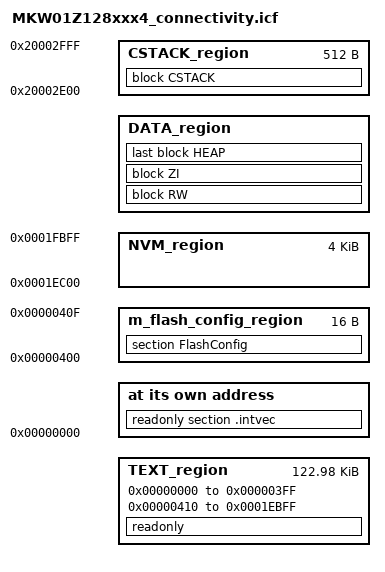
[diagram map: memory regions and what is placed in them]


/* By default, the NVM is not used. */
if (!isdefinedsymbol(gUseNVMLink_d)) {
  define symbol gUseNVMLink_d = 0;
}

/*** ROM: size 128k ***/
/*** RAM: size 16k ***/

/*-Memory Regions-*/
define symbol __region_ROM_start__   = 0x00000000;
define symbol __region_ROM_end__     = 0x0001FFFF;
define symbol __region_RAM_start__   = 0x1FFFF000;
define symbol __region_RAM_end__     = 0x20002FFF;

define symbol __vector_table_size__    =   48*4;
define symbol __ram_vector_table_size__ =  isdefinedsymbol(__ram_vector_table__) ? __vector_table_size__ : 0;



define symbol m_interrupts_start       = __region_ROM_start__;
define symbol m_interrupts_end         = m_interrupts_start + __vector_table_size__ - 1;
  
define symbol m_flash_config_start      = __region_ROM_start__ + 0x00000400;
define symbol m_flash_config_end        = m_flash_config_start + 0x0f;



/*-Sizes-*/
define symbol m_sector_size             = 1024; /* 1k flash sector size */

if (isdefinedsymbol(__stack_size__)) {
  define symbol __size_cstack__        = __stack_size__;
} else {
  define symbol __size_cstack__        = 512;
}

if (isdefinedsymbol(__heap_size__)) {
  define symbol __size_heap__          = __heap_size__;
} else {
  define symbol __size_heap__          = 0;
}


/*** FSL Product Info region ***/
define symbol m_fsl_prodInfo_start     = __region_ROM_end__ - m_sector_size + 1;
define symbol m_fsl_prodInfo_end       = __region_ROM_end__;
define exported symbol FREESCALE_PROD_DATA_BASE_ADDR = m_fsl_prodInfo_start;


/*** NVM Configuration ***/
if( gUseNVMLink_d )
{
  define exported symbol NV_STORAGE_SECTOR_SIZE = m_sector_size; /* 1k flash sector size */
  define exported symbol NV_STORAGE_MAX_SECTORS = 4;     	 /* NV_STORAGE_MAX_SECTORS * NV_STORAGE_SECTOR_SIZE = total NV Storage space */

  define exported symbol NV_STORAGE_START_ADDRESS = m_fsl_prodInfo_start - 1;
  define exported symbol NV_STORAGE_END_ADDRESS = NV_STORAGE_START_ADDRESS - (NV_STORAGE_MAX_SECTORS * NV_STORAGE_SECTOR_SIZE) + 1;
}

/*-Specials-*/
define symbol m_text_start             = m_interrupts_start;
if( gUseNVMLink_d )
{
  define symbol m_text_end               = NV_STORAGE_END_ADDRESS - 1;
}
else
{
  define symbol m_text_end               = m_fsl_prodInfo_start - 1;
}

define symbol m_interrupts_ram_start   = __region_RAM_start__;
define symbol m_interrupts_ram_end     = m_interrupts_ram_start + __ram_vector_table_size__ - 1;

define symbol m_data_start             = m_interrupts_ram_end + 1;
define symbol m_data_end               = __region_RAM_end__;


define exported symbol __VECTOR_TABLE  = m_interrupts_start;
define exported symbol __VECTOR_RAM    = isdefinedsymbol(__ram_vector_table__) ? m_interrupts_ram_start : m_interrupts_start;
define exported symbol __RAM_VECTOR_TABLE_SIZE = __ram_vector_table_size__;
define exported symbol __BOOT_STACK_ADDRESS = m_data_end-0x0F;

define memory mem with size = 4G;
  define region m_flash_config_region = mem:[from m_flash_config_start to m_flash_config_end];
  define region TEXT_region = mem:[from m_text_start to m_flash_config_start - 1] |
                              mem:[from m_flash_config_end + 1 to m_text_end];
if(gUseNVMLink_d) {
  define region NVM_region         = mem:[from NV_STORAGE_END_ADDRESS to NV_STORAGE_START_ADDRESS];
}

define region DATA_region = mem:[from m_data_start to m_data_end-__size_cstack__];
define region CSTACK_region = mem:[from m_data_end-__size_cstack__+1 to m_data_end];
define region m_interrupts_ram_region = mem:[from m_interrupts_ram_start to m_interrupts_ram_end];

define block CSTACK    with alignment = 8, size = __size_cstack__   { };
define block HEAP      with alignment = 8, size = __size_heap__     { };
define block RW        { readwrite };
define block ZI        { zi };

initialize by copy { readwrite, section .textrw };
do not initialize  { section .noinit };

place at address mem: m_interrupts_start    { readonly section .intvec };
place in m_flash_config_region              { section FlashConfig };
place in TEXT_region                        { readonly };
place in DATA_region                        { block RW };
place in DATA_region                        { block ZI };
place in DATA_region                        { last block HEAP };
place in CSTACK_region                      { block CSTACK };

